VERSION "3.4.0"

NS_ :

BS_:

BU_: User ADM_PC_BI25

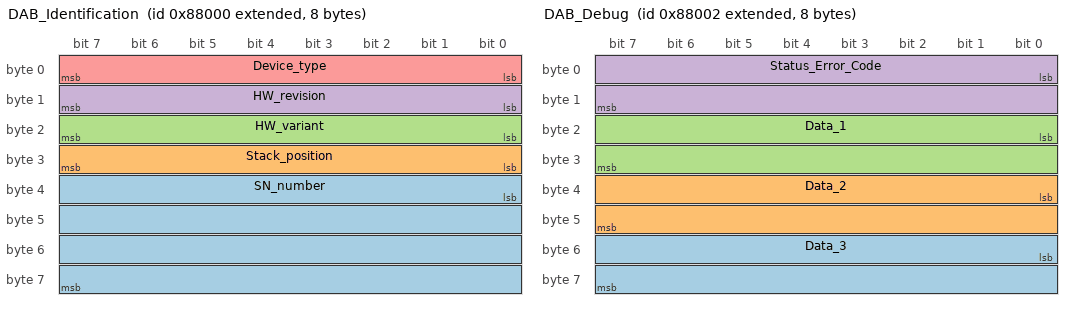
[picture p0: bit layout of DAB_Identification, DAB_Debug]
BO_ 2148040704 DAB_Identification: 8 ADM_PC_BI25
 SG_ SN_number : 32|32@1+ (1,0) [0|0] ""  User
 SG_ Stack_position : 24|8@1+ (1,0) [0|0] ""  User
 SG_ HW_variant : 16|8@1+ (1,0) [0|0] ""  User
 SG_ HW_revision : 8|8@1+ (1,0) [0|0] ""  User
 SG_ Device_type : 0|8@1+ (1,0) [0|0] ""  User

BO_ 2148040705 DAB_FwInfo: 8 ADM_PC_BI25
 SG_ FW_info_mux M : 56|8@1+ (1,0) [0|0] "" Vector__XXX
 SG_ FW_datecode_13 m3 : 48|8@1+ (1,0) [0|0] ""  User
 SG_ FW_datecode_6 m2 : 48|8@1+ (1,0) [0|0] ""  User
 SG_ FW_revision_13 m1 : 48|8@1+ (1,0) [0|0] ""  User
 SG_ FW_revision_6 m0 : 48|8@1+ (1,0) [0|0] ""  User
 SG_ FW_datecode_12 m3 : 40|8@1+ (1,0) [0|0] ""  User
 SG_ FW_datecode_5 m2 : 40|8@1+ (1,0) [0|0] ""  User
 SG_ FW_revision_12 m1 : 40|8@1+ (1,0) [0|0] ""  User
 SG_ FW_revision_5 m0 : 40|8@1+ (1,0) [0|0] ""  User
 SG_ FW_datecode_11 m3 : 32|8@1+ (1,0) [0|0] ""  User
 SG_ FW_datecode_4 m2 : 32|8@1+ (1,0) [0|0] ""  User
 SG_ FW_revision_11 m1 : 32|8@1+ (1,0) [0|0] ""  User
 SG_ FW_revision_4 m0 : 32|8@1+ (1,0) [0|0] ""  User
 SG_ FW_datecode_10 m3 : 24|8@1+ (1,0) [0|0] ""  User
 SG_ FW_datecode_3 m2 : 24|8@1+ (1,0) [0|0] ""  User
 SG_ FW_revision_10 m1 : 24|8@1+ (1,0) [0|0] ""  User
 SG_ FW_revision_3 m0 : 24|8@1+ (1,0) [0|0] ""  User
 SG_ FW_datecode_9 m3 : 16|8@1+ (1,0) [0|0] ""  User
 SG_ FW_datecode_2 m2 : 16|8@1+ (1,0) [0|0] ""  User
 SG_ FW_revision_9 m1 : 16|8@1+ (1,0) [0|0] ""  User
 SG_ FW_revision_2 m0 : 16|8@1+ (1,0) [0|0] ""  User
 SG_ FW_datecode_8 m3 : 8|8@1+ (1,0) [0|0] ""  User
 SG_ FW_datecode_1 m2 : 8|8@1+ (1,0) [0|0] ""  User
 SG_ FW_revision_8 m1 : 8|8@1+ (1,0) [0|0] ""  User
 SG_ FW_revision_1 m0 : 8|8@1+ (1,0) [0|0] ""  User
 SG_ FW_datecode_7 m3 : 0|8@1+ (1,0) [0|0] ""  User
 SG_ FW_datecode_0 m2 : 0|8@1+ (1,0) [0|0] ""  User
 SG_ FW_revision_7 m1 : 0|8@1+ (1,0) [0|0] ""  User
 SG_ FW_revision_0 m0 : 0|8@1+ (1,0) [0|0] ""  User

BO_ 2148040706 DAB_Debug: 8 ADM_PC_BI25
 SG_ Data_3 : 48|16@1+ (1,0) [0|0] ""  User
 SG_ Data_2 : 32|16@1+ (1,0) [0|0] ""  User
 SG_ Data_1 : 16|16@1+ (1,0) [0|0] ""  User
 SG_ Status_Error_Code : 0|16@1+ (1,0) [0|0] ""  User

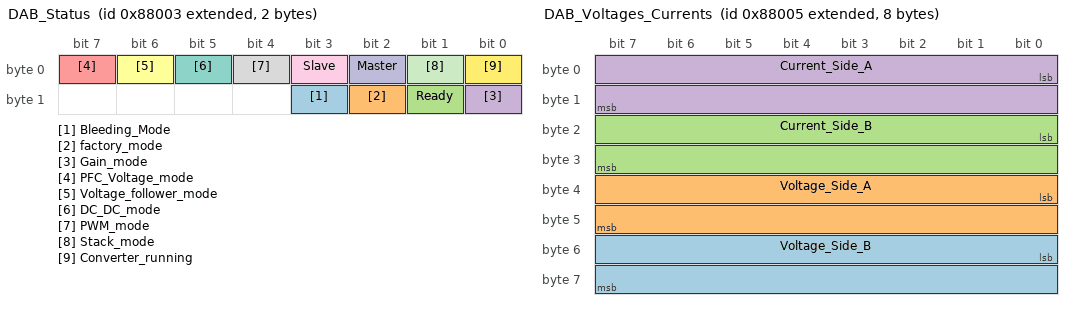
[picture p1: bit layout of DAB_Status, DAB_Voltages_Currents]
BO_ 2148040707 DAB_Status: 2 ADM_PC_BI25
 SG_ Bleeding_Mode : 11|1@1+ (1,0) [0|0] ""  User
 SG_ factory_mode : 10|1@1+ (1,0) [0|0] ""  User
 SG_ Ready : 9|1@1+ (1,0) [0|0] ""  User
 SG_ Gain_mode : 8|1@1+ (1,0) [0|0] ""  User
 SG_ PFC_Voltage_mode : 7|1@1+ (1,0) [0|0] ""  User
 SG_ Voltage_follower_mode : 6|1@1+ (1,0) [0|0] ""  User
 SG_ DC_DC_mode : 5|1@1+ (1,0) [0|0] ""  User
 SG_ PWM_mode : 4|1@1+ (1,0) [0|0] ""  User
 SG_ Slave : 3|1@1+ (1,0) [0|0] ""  User
 SG_ Master : 2|1@1+ (1,0) [0|0] ""  User
 SG_ Stack_mode : 1|1@1+ (1,0) [0|0] ""  User
 SG_ Converter_running : 0|1@1+ (1,0) [0|0] ""  User

BO_ 2148040708 DAB_Faults: 3 ADM_PC_BI25
 SG_ Low_Input_voltage : 23|1@1+ (1,0) [0|0] ""  User
 SG_ Transformer_2_overtemperature : 22|1@1+ (1,0) [0|0] ""  User
 SG_ Transformer_1_overtemperature : 21|1@1+ (1,0) [0|0] ""  User
 SG_ WCH : 20|1@1+ (1,0) [0|0] ""  User
 SG_ ADC : 19|1@1+ (1,0) [0|0] ""  User
 SG_ NFO : 18|1@1+ (1,0) [0|0] ""  User
 SG_ System : 17|1@1+ (1,0) [0|0] ""  User
 SG_ EEPROM_failure : 16|1@1+ (1,0) [0|0] ""  User
 SG_ Measurement_system_failure : 15|1@1+ (1,0) [0|0] ""  User
 SG_ Control_response_timedout : 14|1@1+ (1,0) [0|0] ""  User
 SG_ CAN_failure : 13|1@1+ (1,0) [0|0] ""  User
 SG_ Switching_failure : 12|1@1+ (1,0) [0|0] ""  User
 SG_ Bar_B_overtemperature : 11|1@1+ (1,0) [0|0] ""  User
 SG_ Bar_A_overtemperature : 10|1@1+ (1,0) [0|0] ""  User
 SG_ Voltage_Side_B_overvoltage : 9|1@1+ (1,0) [0|0] ""  User
 SG_ Voltage_Side_B_undervoltage : 8|1@1+ (1,0) [0|0] ""  User
 SG_ Voltage_Side_A_overvoltage : 7|1@1+ (1,0) [0|0] ""  User
 SG_ Voltage_Side_A_undervoltage : 6|1@1+ (1,0) [0|0] ""  User
 SG_ Current_Phase_Side_B_overcurrent : 5|1@1+ (1,0) [0|0] ""  User
 SG_ Current_Phase_Side_A_overcurrent : 4|1@1+ (1,0) [0|0] ""  User
 SG_ Current_Side_B_overcurrent : 3|1@1+ (1,0) [0|0] ""  User
 SG_ Current_Side_A_overcurrent : 2|1@1+ (1,0) [0|0] ""  User
 SG_ Protection_trip_external : 1|1@1+ (1,0) [0|0] ""  User
 SG_ Protection_trip_internal : 0|1@1+ (1,0) [0|0] ""  User

BO_ 2148040709 DAB_Voltages_Currents: 8 ADM_PC_BI25
 SG_ Voltage_Side_B : 48|16@1- (0.1,0) [0|0] "V"  User
 SG_ Voltage_Side_A : 32|16@1- (0.1,0) [0|0] "V"  User
 SG_ Current_Side_B : 16|16@1- (0.01,0) [0|0] "A"  User
 SG_ Current_Side_A : 0|16@1- (0.01,0) [0|0] "A"  User

BO_ 2148040710 DAB_Phase_Currents: 4 ADM_PC_BI25
 SG_ Current_Phase_Side_B : 16|16@1- (0.01,0) [0|0] "A"  User
 SG_ Current_Phase_Side_A : 0|16@1- (0.01,0) [0|0] "A"  User

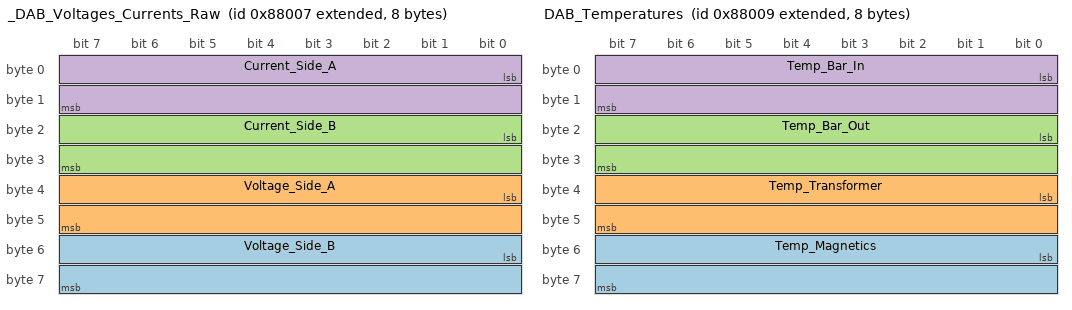
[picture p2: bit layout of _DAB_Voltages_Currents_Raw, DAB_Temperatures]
BO_ 2148040711 _DAB_Voltages_Currents_Raw: 8 ADM_PC_BI25
 SG_ Voltage_Side_B : 48|16@1- (1,0) [0|0] ""  User
 SG_ Voltage_Side_A : 32|16@1+ (1,0) [0|0] ""  User
 SG_ Current_Side_B : 16|16@1- (1,0) [0|0] ""  User
 SG_ Current_Side_A : 0|16@1+ (1,0) [0|0] ""  User

BO_ 2148040712 _DAB_Phase_Currents_Raw: 8 ADM_PC_BI25
 SG_ Current_Phase_Side_B : 16|16@1+ (1,0) [0|0] ""  User
 SG_ Current_Phase_Side_A : 0|16@1+ (1,0) [0|0] ""  User

BO_ 2148040713 DAB_Temperatures: 8 ADM_PC_BI25
 SG_ Temp_Magnetics : 48|16@1- (0.01,0) [0|0] "°C"  User
 SG_ Temp_Transformer : 32|16@1- (0.01,0) [0|0] "°C"  User
 SG_ Temp_Bar_Out : 16|16@1- (0.01,0) [0|0] "°C"  User
 SG_ Temp_Bar_In : 0|16@1- (0.01,0) [0|0] "°C"  User

BO_ 2148040714 DAB_Setpoints_PWM_Phase: 4 ADM_PC_BI25
 SG_ Phase_B : 16|16@1- (0.003,0) [0|0] "°"  User
 SG_ Phase_A : 0|16@1- (0.003,0) [0|0] "°"  User

BO_ 2148040718 _DAB_Broadcast: 8 User
 SG_ Diagnostics_Index M : 56|8@1+ (1,0) [0|0] "" Vector__XXX
 SG_ Port_B m1 : 24|16@1- (0.01,0) [0|0] "A"  ADM_PC_BI25
 SG_ Port_A m1 : 8|16@1- (0.01,0) [0|0] "A"  ADM_PC_BI25
 SG_ Group_ID : 5|3@1+ (1,0) [0|0] ""  ADM_PC_BI25
 SG_ Stack_position : 0|5@1+ (1,0) [0|0] ""  ADM_PC_BI25

BO_ 2148040719 DAB_Group_Info: 1 ADM_PC_BI25
 SG_ Group_ID : 0|8@1+ (1,0) [0|0] ""  User

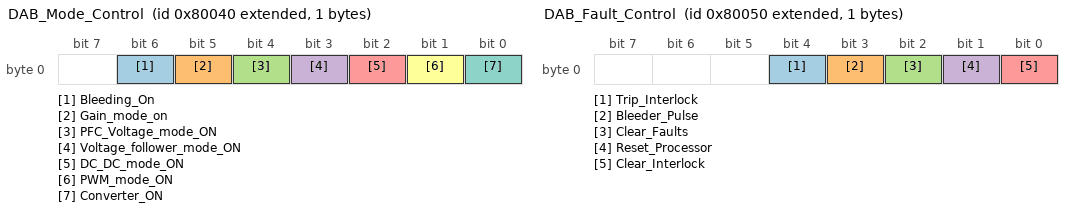
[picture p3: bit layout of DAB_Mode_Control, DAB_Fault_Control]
BO_ 2148008000 DAB_Mode_Control: 1 User
 SG_ Bleeding_On : 6|1@1+ (1,0) [0|0] ""  ADM_PC_BI25
 SG_ Gain_mode_on : 5|1@1+ (1,0) [0|0] ""  ADM_PC_BI25
 SG_ PFC_Voltage_mode_ON : 4|1@1+ (1,0) [0|0] ""  ADM_PC_BI25
 SG_ Voltage_follower_mode_ON : 3|1@1+ (1,0) [0|0] ""  ADM_PC_BI25
 SG_ DC_DC_mode_ON : 2|1@1+ (1,0) [0|0] ""  ADM_PC_BI25
 SG_ PWM_mode_ON : 1|1@1+ (1,0) [0|0] ""  ADM_PC_BI25
 SG_ Converter_ON : 0|1@1+ (1,0) [0|0] ""  ADM_PC_BI25

BO_ 2148008012 DAB_Group_Control: 1 User
 SG_ Group_ID : 0|8@1+ (1,0) [0|0] ""  ADM_PC_BI25

BO_ 2148008016 DAB_Fault_Control: 1 User
 SG_ Trip_Interlock : 4|1@1+ (1,0) [0|0] ""  ADM_PC_BI25
 SG_ Bleeder_Pulse : 3|1@1+ (1,0) [0|0] ""  ADM_PC_BI25
 SG_ Clear_Faults : 2|1@1+ (1,0) [0|0] ""  ADM_PC_BI25
 SG_ Reset_Processor : 1|1@1+ (1,0) [0|0] ""  ADM_PC_BI25
 SG_ Clear_Interlock : 0|1@1+ (1,0) [0|0] ""  ADM_PC_BI25

BO_ 2148008006 DAB_Current_Setpoint_Control: 4 User
 SG_ Negative_Current_setpoint : 16|16@1- (0.01,0) [-55|55] "A"  ADM_PC_BI25
 SG_ Positive_Current_setpoint : 0|16@1- (0.01,0) [-55|55] "A"  ADM_PC_BI25

BO_ 2148008007 DAB_Voltage_Setpoint_Control: 2 User
 SG_ Voltage_setpoint : 0|16@1+ (0.1,0) [0|1000] "V"  ADM_PC_BI25

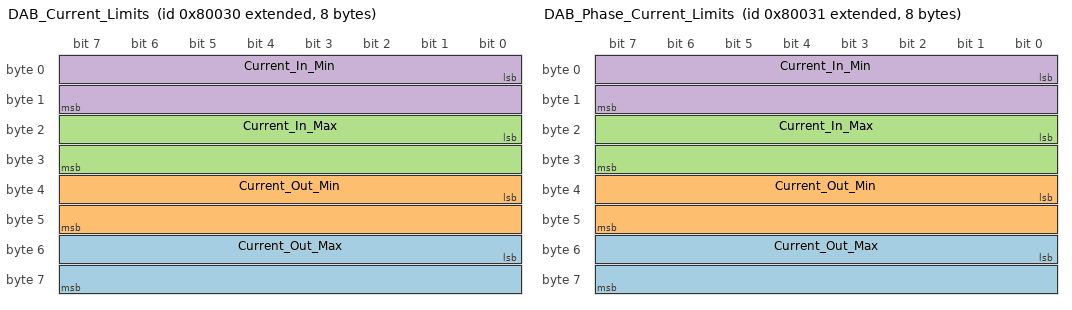
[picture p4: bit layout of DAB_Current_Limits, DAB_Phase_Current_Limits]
BO_ 2148007984 DAB_Current_Limits: 8 User
 SG_ Current_Out_Max : 48|16@1- (0.01,0) [-60|60] "A"  ADM_PC_BI25
 SG_ Current_Out_Min : 32|16@1- (0.01,0) [-60|60] "A"  ADM_PC_BI25
 SG_ Current_In_Max : 16|16@1- (0.01,0) [-60|60] "A"  ADM_PC_BI25
 SG_ Current_In_Min : 0|16@1- (0.01,0) [-60|60] "A"  ADM_PC_BI25

BO_ 2148007985 DAB_Phase_Current_Limits: 8 User
 SG_ Current_Out_Max : 48|16@1- (0.01,0) [-60|60] "A"  ADM_PC_BI25
 SG_ Current_Out_Min : 32|16@1- (0.01,0) [-60|60] "A"  ADM_PC_BI25
 SG_ Current_In_Max : 16|16@1- (0.01,0) [-60|60] "A"  ADM_PC_BI25
 SG_ Current_In_Min : 0|16@1- (0.01,0) [-60|60] "A"  ADM_PC_BI25

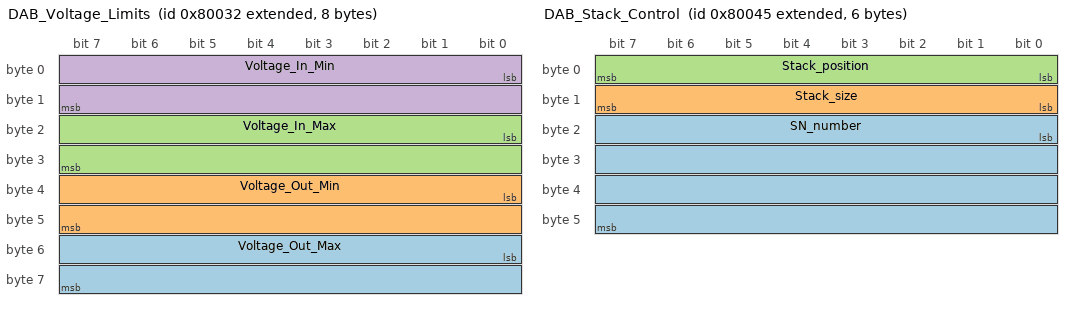
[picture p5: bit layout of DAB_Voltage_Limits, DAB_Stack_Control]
BO_ 2148007986 DAB_Voltage_Limits: 8 User
 SG_ Voltage_Out_Max : 48|16@1- (0.1,0) [0|850] "V"  ADM_PC_BI25
 SG_ Voltage_Out_Min : 32|16@1- (0.1,0) [0|850] "V"  ADM_PC_BI25
 SG_ Voltage_In_Max : 16|16@1- (0.1,0) [0|850] "V"  ADM_PC_BI25
 SG_ Voltage_In_Min : 0|16@1- (0.1,0) [0|850] "V"  ADM_PC_BI25

BO_ 2148040769 _DAB_Calibration_Adc_Fs: 6 ADM_PC_BI25
 SG_ Adc_Index M : 32|16@1+ (1,0) [0|0] "" Vector__XXX
 SG_ Current_Phase_Side_B m5 : 0|32@1+ (1,0) [0|0] "Fullscale"  User
 SG_ Voltage_Side_B m4 : 0|32@1+ (1,0) [0|0] "Fullscale"  User
 SG_ Voltage_Side_A m3 : 0|32@1+ (1,0) [0|0] "Fullscale"  User
 SG_ Current_Phase_Side_A m2 : 0|32@1+ (1,0) [0|0] "Fullscale"  User
 SG_ Current_Side_B m1 : 0|32@1+ (1,0) [0|0] "Fullscale"  User
 SG_ Current_Side_A m0 : 0|32@1+ (1,0) [0|0] "Fullscale"  User

BO_ 2148008001 _DAB_Calibration_Offset_Update: 6 User
 SG_ CRC : 32|16@1+ (1,0) [0|0] "-"  ADM_PC_BI25
 SG_ Calibration_Index M : 16|16@1+ (1,0) [0|0] "" Vector__XXX
 SG_ Current_Phase_Side_B m5 : 0|16@1- (1,0) [0|0] "ADC Counts"  ADM_PC_BI25
 SG_ Voltage_Side_B m4 : 0|16@1- (1,0) [0|0] "ADC Counts"  ADM_PC_BI25
 SG_ Voltage_Side_A m3 : 0|16@1- (1,0) [0|0] "ADC Counts"  ADM_PC_BI25
 SG_ Current_Phase_Side_A m2 : 0|16@1- (1,0) [0|0] "ADC Counts"  ADM_PC_BI25
 SG_ Current_Side_B m1 : 0|16@1- (1,0) [0|0] "ADC Counts"  ADM_PC_BI25
 SG_ Current_Side_A m0 : 0|16@1- (1,0) [0|0] "ADC Counts"  ADM_PC_BI25

BO_ 2148008002 _DAB_Calibration_Scale_Update: 6 User
 SG_ CRC : 32|16@1+ (1,0) [0|0] "-"  ADM_PC_BI25
 SG_ Calibration_Index M : 16|16@1+ (1,0) [0|0] "" Vector__XXX
 SG_ Current_Phase_Side_B m5 : 0|16@1- (1,0) [0|0] "ADC Counts"  ADM_PC_BI25
 SG_ Voltage_Side_B m4 : 0|16@1- (1,0) [0|0] "ADC Counts"  ADM_PC_BI25
 SG_ Voltage_Side_A m3 : 0|16@1- (1,0) [0|0] "ADC Counts"  ADM_PC_BI25
 SG_ Current_Phase_Side_A m2 : 0|16@1- (1,0) [0|0] "ADC Counts"  ADM_PC_BI25
 SG_ Current_Side_B m1 : 0|16@1- (1,0) [0|0] "ADC Counts"  ADM_PC_BI25
 SG_ Current_Side_A m0 : 0|16@1- (1,0) [0|0] "ADC Counts"  ADM_PC_BI25

BO_ 2148040770 _DAB_Calibration_Adc_Scale: 6 ADM_PC_BI25
 SG_ Adc_Index M : 32|16@1+ (1,0) [0|0] "" Vector__XXX
 SG_ Current_Phase_Side_B m5 : 0|32@1+ (1,0) [0|0] "1 / adc_bins"  User
 SG_ Voltage_Side_B m4 : 0|32@1- (1,0) [0|0] "1 / adc_bins"  User
 SG_ Voltage_Side_A m3 : 0|32@1- (1,0) [0|0] "1 / adc_bins"  User
 SG_ Current_Phase_Side_A m2 : 0|32@1- (1,0) [0|0] "1 / adc_bins"  User
 SG_ Current_Side_B m1 : 0|32@1- (1,0) [0|0] "1 / adc_bins"  User
 SG_ Current_Side_A m0 : 0|32@1- (1,0) [0|0] "1 / adc_bins"  User

BO_ 2148008003 DAB_PWM_Phase_Control: 4 User
 SG_ Phase_B : 16|16@1- (0.003,0) [0|0] "°"  ADM_PC_BI25
 SG_ Phase_A : 0|16@1- (0.003,0) [0|0] "°"  ADM_PC_BI25

BO_ 2148008004 CLLC_PWM_Frequency_Control: 2 User
 SG_ PWM_frequency : 0|16@1+ (10,0) [0|0] "Hz"  ADM_PC_BI25

BO_ 2148040776 CLLC_PWM_Frequency_value: 4 ADM_PC_BI25
 SG_ frequency : 0|16@1+ (10,0) [0|0] "Hz"  User

BO_ 2148008005 DAB_Stack_Control: 6 User
 SG_ SN_number : 16|32@1+ (1,0) [0|0] ""  ADM_PC_BI25
 SG_ Stack_size : 8|8@1+ (1,0) [0|0] ""  ADM_PC_BI25
 SG_ Stack_position : 0|8@1+ (1,0) [0|0] ""  ADM_PC_BI25

BO_ 2148008008 CLLC_PWM_Gain_Control: 2 User
 SG_ Gain : 0|16@1+ (0.01,0) [0|0] "none"  ADM_PC_BI25

BO_ 2148040849 Data_phase_shift: 4 ADM_PC_BI25
 SG_ phase_shift_b : 16|16@1+ (0.1,0) [0|0] "Hz"  User
 SG_ phase_shift_a : 0|16@1- (0.1,0) [0|0] "V"  User

BO_ 2148008009 CLLC_PWM_Phase_Mode: 1 User
 SG_ phase_mode : 0|8@1+ (1,0) [0|0] ""  ADM_PC_BI25

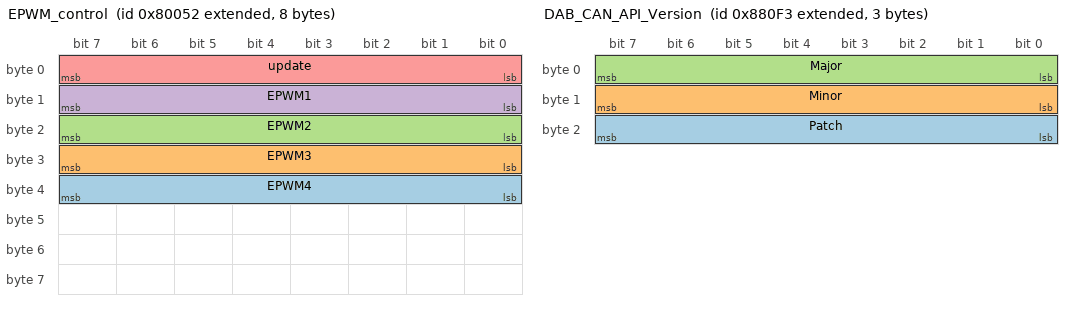
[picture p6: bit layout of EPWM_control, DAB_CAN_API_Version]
BO_ 2148008018 EPWM_control: 8 User
 SG_ EPWM4 : 32|8@1+ (1,0) [0|0] ""  ADM_PC_BI25
 SG_ EPWM3 : 24|8@1+ (1,0) [0|0] ""  ADM_PC_BI25
 SG_ EPWM2 : 16|8@1+ (1,0) [0|0] ""  ADM_PC_BI25
 SG_ EPWM1 : 8|8@1+ (1,0) [0|0] ""  ADM_PC_BI25
 SG_ update : 0|8@1+ (1,0) [0|0] ""  ADM_PC_BI25

BO_ 2148040947 DAB_CAN_API_Version: 3 ADM_PC_BI25
 SG_ Patch : 16|8@1+ (1,0) [0|0] ""  User
 SG_ Minor : 8|8@1+ (1,0) [0|0] ""  User
 SG_ Major : 0|8@1+ (1,0) [0|0] ""  User

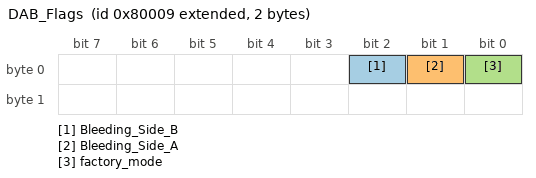
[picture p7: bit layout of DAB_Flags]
BO_ 2148007945 DAB_Flags: 2 User
 SG_ Bleeding_Side_B : 2|1@1+ (1,0) [0|0] ""  ADM_PC_BI25
 SG_ Bleeding_Side_A : 1|1@1+ (1,0) [0|0] ""  ADM_PC_BI25
 SG_ factory_mode : 0|1@1+ (1,0) [0|0] ""  ADM_PC_BI25

BO_ 2148040959 CLLC_Fault_Label: 4 ADM_PC_BI25
 SG_ Faults : 0|16@1+ (1,0) [0|0] ""  User

BO_ 2148008106 ADB_Schedule_Flag: 2 User
 SG_ ADB_Preset_1 : 0|1@1+ (1,0) [0|0] ""  ADM_PC_BI25

CM_ BO_ 2148040704 "Identification of the device";
CM_ SG_ 2148040704 SN_number "Unique module serial number";
CM_ SG_ 2148040704 Stack_position "Position of the module within the stack";
CM_ SG_ 2148040704 HW_variant "The DSP firmware revision number";
CM_ SG_ 2148040704 HW_revision "The hardware revision number";
CM_ SG_ 2148040704 Device_type " The device identification field, uniquely identifies the sender in the network. ";
CM_ BO_ 2148040705 "Git revision of the DSP firmware";
CM_ SG_ 2148040705 FW_datecode_13 "Character 13";
CM_ SG_ 2148040705 FW_datecode_6 "Character 3";
CM_ SG_ 2148040705 FW_revision_13 "Character 13";
CM_ SG_ 2148040705 FW_revision_6 "Character 3";
CM_ SG_ 2148040705 FW_datecode_12 "Character 12";
CM_ SG_ 2148040705 FW_datecode_5 "Character 3";
CM_ SG_ 2148040705 FW_revision_12 "Character 12";
CM_ SG_ 2148040705 FW_revision_5 "Character 3";
CM_ SG_ 2148040705 FW_datecode_11 "Character 11";
CM_ SG_ 2148040705 FW_datecode_4 "Character 3";
CM_ SG_ 2148040705 FW_revision_11 "Character 11";
CM_ SG_ 2148040705 FW_revision_4 "Character 3";
CM_ SG_ 2148040705 FW_datecode_10 "Character 10";
CM_ SG_ 2148040705 FW_datecode_3 "Character 3";
CM_ SG_ 2148040705 FW_revision_10 "Character 10";
CM_ SG_ 2148040705 FW_revision_3 "Character 3";
CM_ SG_ 2148040705 FW_datecode_9 "Character 9";
CM_ SG_ 2148040705 FW_datecode_2 "Character 2";
CM_ SG_ 2148040705 FW_revision_9 "Character 9";
CM_ SG_ 2148040705 FW_revision_2 "Character 2";
CM_ SG_ 2148040705 FW_datecode_8 "Character 8";
CM_ SG_ 2148040705 FW_datecode_1 "Character 1";
CM_ SG_ 2148040705 FW_revision_8 "Character 8";
CM_ SG_ 2148040705 FW_revision_1 "Character 1";
CM_ SG_ 2148040705 FW_datecode_7 "Character 7";
CM_ SG_ 2148040705 FW_datecode_0 "Character 0";
CM_ SG_ 2148040705 FW_revision_7 "Character 7";
CM_ SG_ 2148040705 FW_revision_0 "Character 0";
CM_ BO_ 2148040706 "Values for debugging of HW/SW problems";
CM_ SG_ 2148040706 Data_3 "Additional information for the error/status";
CM_ SG_ 2148040706 Data_2 "Additional information for the error/status";
CM_ SG_ 2148040706 Data_1 "Additional information for the error/status";
CM_ SG_ 2148040706 Status_Error_Code "Main status / error code as defined in errno/errno.h";
CM_ BO_ 2148040707 "Status bitfield";
CM_ SG_ 2148040707 Bleeding_Mode "Indicates if converter is in Bleeding mode.";
CM_ SG_ 2148040707 factory_mode "Indicates if converter is in factory mode.";
CM_ SG_ 2148040707 Ready "Indicates if converter is ready for operation.";
CM_ SG_ 2148040707 Gain_mode " Indicates if the converter is in Gain Mode.";
CM_ SG_ 2148040707 PFC_Voltage_mode " Indicates if the converter is in PFC Voltage mode. ";
CM_ SG_ 2148040707 Voltage_follower_mode " Indicates if the converter is in Voltage follower mode. ";
CM_ SG_ 2148040707 DC_DC_mode " Indicates if the converter is in DC DC mode with automatic bi-dir angle control. ";
CM_ SG_ 2148040707 PWM_mode " Indicates if the converter is in PWM mode, and therefore working in open loop. ";
CM_ SG_ 2148040707 Slave "Indicates if the current converter is a Slave in the stack.";
CM_ SG_ 2148040707 Master "Indicates if the current converter is the Master in the stack.";
CM_ SG_ 2148040707 Stack_mode "Indicates if running in stack mode.";
CM_ SG_ 2148040707 Converter_running "Indicates that the converter is running, and its output is active.";
CM_ BO_ 2148040708 "Fault bitfield";
CM_ SG_ 2148040708 Low_Input_voltage "
            This flag is asserted when the Input voltage is low than 500V.
        ";
CM_ SG_ 2148040708 Transformer_2_overtemperature "
            This flag is asserted when the temperature of the Bar B block is too high.
        ";
CM_ SG_ 2148040708 Transformer_1_overtemperature "
            This flag is asserted when the temperature of the Bar B block is too high.
        ";
CM_ SG_ 2148040708 EEPROM_failure "
            The configuration EEPROM failed to load or save the module configuration.
        ";
CM_ SG_ 2148040708 Measurement_system_failure "
            The voltages/currents measurement system is malfunctionning, and readouts are not
            guaranteed to be accurate.
        ";
CM_ SG_ 2148040708 Control_response_timedout "
            The control system did not answer within the allowed time window, and a time out
            condition was triggered. The converter is switched off as the control system is
            not present.
        ";
CM_ SG_ 2148040708 CAN_failure "
            CAN bus or transceiver not operating properly.
        ";
CM_ SG_ 2148040708 Switching_failure "
            Failure in the MOSFET block or in their drivers.
        ";
CM_ SG_ 2148040708 Bar_B_overtemperature "
            This flag is asserted when the temperature of the Bar B block is too high.
        ";
CM_ SG_ 2148040708 Bar_A_overtemperature "
            This flag is asserted when the temperature of the Bar A block is too high.
        ";
CM_ SG_ 2148040708 Voltage_Side_B_overvoltage "
            Indicates an overvoltage event Voltage Out. The overvoltage event is triggered when
            the measured phase voltage is over the programmed / absolute voltage limit.
        ";
CM_ SG_ 2148040708 Voltage_Side_B_undervoltage "
            Indicates an undervoltage event on Voltage Out. The undervoltage event is triggered
            when the measured voltage is under the programmed / absolute voltage limit.
        ";
CM_ SG_ 2148040708 Voltage_Side_A_overvoltage "
            Indicates an overvoltage event Voltage In. The overvoltage event is triggered when
            the measured phase voltage is over the programmed / absolute voltage limit.
        ";
CM_ SG_ 2148040708 Voltage_Side_A_undervoltage "
            Indicates an undervoltage event on Voltage In. The undervoltage event is triggered
            when the measured voltage is under the programmed / absolute voltage limit.
        ";
CM_ SG_ 2148040708 Current_Phase_Side_B_overcurrent "
            Indicates an overcurrent event on output phase current. The overcurrent event is
            triggered when the measured current is over the programmed / absolute current limit.
        ";
CM_ SG_ 2148040708 Current_Phase_Side_A_overcurrent "
            Indicates an overcurrent event on input phase current. The overcurrent event is
            triggered when the measured current is over the programmed / absolute current limit.
        ";
CM_ SG_ 2148040708 Current_Side_B_overcurrent "
            Indicates an overcurrent event on output current. The overcurrent event is
            triggered when the measured current is over the programmed / absolute current limit.
        ";
CM_ SG_ 2148040708 Current_Side_A_overcurrent "
            Indicates an overcurrent event on input current. The overcurrent event is triggered
            when the measured phase current is over the programmed / absolute current limit.
        ";
CM_ SG_ 2148040708 Protection_trip_external " This flag is asserted if the interlock is open due to an external condition received in the module. ";
CM_ SG_ 2148040708 Protection_trip_internal " This flag is asserted if the interlock is open due to an internal fault condition (self-protection). ";
CM_ BO_ 2148040709 "Voltages and currents of Input/Output";
CM_ SG_ 2148040709 Voltage_Side_B "Output voltage of the converter.";
CM_ SG_ 2148040709 Voltage_Side_A "Input voltage of the converter.";
CM_ SG_ 2148040709 Current_Side_B " Input current of the converter (direction from input to output is positive). ";
CM_ SG_ 2148040709 Current_Side_A " Input current of the converter (direction from input to output is positive). ";
CM_ BO_ 2148040710 "Phase currents of Input/Output";
CM_ SG_ 2148040710 Current_Phase_Side_B " Input phase current of the converter (direction from input to output is positive). ";
CM_ SG_ 2148040710 Current_Phase_Side_A " Input phase current of the converter (direction from input to output is positive). ";
CM_ BO_ 2148040711 "Raw Voltages and currents of Input/Output";
CM_ BO_ 2148040712 "Raw ADC values from the Phase current sensors";
CM_ BO_ 2148040713 "Readouts of the module temperature sensors";
CM_ SG_ 2148040713 Temp_Magnetics "Temperature of the Magnetic B block";
CM_ SG_ 2148040713 Temp_Transformer "Temperature of the Bar B block";
CM_ SG_ 2148040713 Temp_Bar_Out "Temperature of the Bar A block";
CM_ SG_ 2148040713 Temp_Bar_In "Temperature of the Bar A block";
CM_ BO_ 2148040714 "PWM duty cycle control";
CM_ SG_ 2148040714 Phase_B "PWM Phase setpoint.";
CM_ SG_ 2148040714 Phase_A "PWM Phase setpoint.";
CM_ BO_ 2148040718 "All DABs will listen to this message";
CM_ SG_ 2148040718 Port_B "'Output' port B current.";
CM_ SG_ 2148040718 Port_A "'Input' port A current. ";
CM_ SG_ 2148040718 Group_ID "Sender Group ID";
CM_ SG_ 2148040718 Stack_position "Sender Stack position";
CM_ BO_ 2148040719 "Contains the Group ID of the device";
CM_ SG_ 2148040719 Group_ID "Group ID of the device";
CM_ BO_ 2148008000 "Operation Mode control: sets the converter operation mode";
CM_ SG_ 2148008000 Bleeding_On "Enable the Bleeding mode (this will set the converter in open loop).";
CM_ SG_ 2148008000 Gain_mode_on "Enable the GAIN mode (this will set the converter in open loop).";
CM_ SG_ 2148008000 PFC_Voltage_mode_ON "This mode regulates output (port B) current/voltage while sending voltage commands to an Upstream AFE working as PFC (AC to DC), to ensure a 1:1 voltage ratio.";
CM_ SG_ 2148008000 Voltage_follower_mode_ON "This mode will regulate a 1:1 ratio voltage from A to B (A is reference voltage)";
CM_ SG_ 2148008000 DC_DC_mode_ON "Enable the DC DC mode (this will set the converter in automatic angle control). ";
CM_ SG_ 2148008000 PWM_mode_ON "Enable the PWM mode (this will set the converter in open loop).";
CM_ SG_ 2148008000 Converter_ON "Enable the converter";
CM_ BO_ 2148008012 "Set the Group ID of the device";
CM_ SG_ 2148008012 Group_ID "Desired group ID for the device";
CM_ BO_ 2148008016 "Fault Control: actions to clear faults and reset the system";
CM_ SG_ 2148008016 Trip_Interlock "Trips the converter interlock";
CM_ SG_ 2148008016 Bleeder_Pulse "Bleed out output";
CM_ SG_ 2148008016 Clear_Faults "Clear software faults";
CM_ SG_ 2148008016 Reset_Processor "Reset the converter DSP";
CM_ SG_ 2148008016 Clear_Interlock "Clears the converter interlock";
CM_ BO_ 2148008006 "Current setpoint control";
CM_ SG_ 2148008006 Negative_Current_setpoint "Sets the port B negative current setpoint.";
CM_ SG_ 2148008006 Positive_Current_setpoint "Sets the port B positive current setpoint.";
CM_ BO_ 2148008007 "Voltage setpoint control";
CM_ SG_ 2148008007 Voltage_setpoint "Sets the output voltage setpoint";
CM_ SG_ 2148007984 Current_Out_Max "Maximum allowable output current of the converter.";
CM_ SG_ 2148007984 Current_Out_Min "Minimum allowable output current of the converter.";
CM_ SG_ 2148007984 Current_In_Max "Maximum allowable input current of the converter.";
CM_ SG_ 2148007984 Current_In_Min "Minimum allowable input current of the converter.";
CM_ SG_ 2148007985 Current_Out_Max "Maximum allowable output current of the converter.";
CM_ SG_ 2148007985 Current_Out_Min "Minimum allowable output current of the converter.";
CM_ SG_ 2148007985 Current_In_Max "Maximum allowable input current of the converter.";
CM_ SG_ 2148007985 Current_In_Min "Minimum allowable input current of the converter.";
CM_ BO_ 2148007986 "Set the voltage limits (mminimum and maximum)";
CM_ SG_ 2148007986 Voltage_Out_Max "Minimum allowable output voltage of the converter.";
CM_ SG_ 2148007986 Voltage_Out_Min "Minimum allowable output voltage of the converter.";
CM_ SG_ 2148007986 Voltage_In_Max "Minimum allowable input voltage of the converter.";
CM_ SG_ 2148007986 Voltage_In_Min "Minimum allowable input voltage of the converter.";
CM_ BO_ 2148040769 " Fullscale value of readouts. ";
CM_ BO_ 2148008001 "Update of the calibration table for offsets.";
CM_ SG_ 2148008001 CRC " Checksum of bytes 0 to 2, CRC-CCITT, corresponding to qChecksum (www.qt.io) ";
CM_ BO_ 2148008002 "Update of the calibration table for scales.";
CM_ SG_ 2148008002 CRC " Checksum of bytes 0 to 2, CRC-CCITT, corresponding to qChecksum (www.qt.io) ";
CM_ BO_ 2148040770 " Adc scale (resolution) value of readouts. ";
CM_ BO_ 2148008003 "PWM duty cycle control";
CM_ SG_ 2148008003 Phase_B "PWM Phase setpoint";
CM_ SG_ 2148008003 Phase_A "PWM Phase setpoint";
CM_ BO_ 2148008004 "PWM frequency control";
CM_ SG_ 2148008004 PWM_frequency "Sets the PWM frequency. Active only when the converter is in PWM mode";
CM_ BO_ 2148040776 "PWM duty cycle Readout";
CM_ SG_ 2148040776 frequency "PWM frequency setpoint.";
CM_ BO_ 2148008005 "PFC stack control";
CM_ SG_ 2148008005 SN_number "Unique module serial number";
CM_ SG_ 2148008005 Stack_size "How many PFC converters are in stack in total";
CM_ SG_ 2148008005 Stack_position "The converter position within the stack";
CM_ BO_ 2148008008 "PWM gain control";
CM_ SG_ 2148008008 Gain "Sets voltage gain in open loop";
CM_ BO_ 2148040849 "Readouts of the module phase shifts";
CM_ SG_ 2148040849 phase_shift_b "Phase_shift_B of the Bar A block";
CM_ SG_ 2148040849 phase_shift_a "Phase_shift_A of the Bar A block";
CM_ BO_ 2148008009 "PWM duty cycle control";
CM_ SG_ 2148008009 phase_mode "PWM Phase shift mode/gain mode";
CM_ BO_ 2148008018 "Control the EPWM_control";
CM_ SG_ 2148008018 EPWM4 "Customers MUST NOT USE this bit. If set to 1, EPWM is turned on. ";
CM_ SG_ 2148008018 EPWM3 "Customers MUST NOT USE this bit. If set to 1, EPWM is turned on. ";
CM_ SG_ 2148008018 EPWM2 "Customers MUST NOT USE this bit. If set to 1, EPWM is turned on. ";
CM_ SG_ 2148008018 EPWM1 "Customers MUST NOT USE this bit. If set to 1, EPWM is turned on. ";
CM_ SG_ 2148008018 update "Customers MUST NOT USE this bit. If set to 1, EPWM is turned on. ";
CM_ BO_ 2148040947 "This message declares the version of the API that is provided by the converter. The version follows newer convention.";
CM_ SG_ 2148040947 Patch "The Patch number. This number increases when changes to descriptions and documentation/comments are made";
CM_ SG_ 2148040947 Minor "The Minor version number. This number increases if there are backwards compatible changes, like new messages or the use of previously reserved space";
CM_ SG_ 2148040947 Major "The Major version number. This number increases if there are backwards incompatible changes";
CM_ BO_ 2148007945 "All Flags of the converter";
CM_ SG_ 2148007945 Bleeding_Side_B "Enable Bleeding_Side_B mode";
CM_ SG_ 2148007945 Bleeding_Side_A "Enable Bleeding_Side_A mode";
CM_ SG_ 2148007945 factory_mode "Enable Factory mode";
CM_ BO_ 2148040959 "This message tells the General Status of the converter.";
CM_ SG_ 2148040959 Faults "Faults state";
CM_ BO_ 2148008106 "Chnage to preset of CAN messages for ADB converter";
CM_ SG_ 2148008106 ADB_Preset_1 "Enable Preset mode";
BA_DEF_ BO_  "GenMsgCycleTime" INT 0 65535;
BA_DEF_DEF_  "GenMsgCycleTime" 0;
BA_ "GenMsgCycleTime" BO_ 2148040704 1000;
BA_ "GenMsgCycleTime" BO_ 2148040705 1000;
BA_ "GenMsgCycleTime" BO_ 2148040706 1000;
BA_ "GenMsgCycleTime" BO_ 2148040707 100;
BA_ "GenMsgCycleTime" BO_ 2148040708 1000;
BA_ "GenMsgCycleTime" BO_ 2148040709 100;
BA_ "GenMsgCycleTime" BO_ 2148040710 100;
BA_ "GenMsgCycleTime" BO_ 2148040711 100;
BA_ "GenMsgCycleTime" BO_ 2148040712 100;
BA_ "GenMsgCycleTime" BO_ 2148040713 1000;
BA_ "GenMsgCycleTime" BO_ 2148040714 1000;
BA_ "GenMsgCycleTime" BO_ 2148040718 50;
BA_ "GenMsgCycleTime" BO_ 2148040719 1000;
BA_ "GenMsgCycleTime" BO_ 2148008000 100;
BA_ "GenMsgCycleTime" BO_ 2148008006 100;
BA_ "GenMsgCycleTime" BO_ 2148008007 100;
BA_ "GenMsgCycleTime" BO_ 2148040769 1000;
BA_ "GenMsgCycleTime" BO_ 2148040770 1000;
BA_ "GenMsgCycleTime" BO_ 2148040776 1000;
BA_ "GenMsgCycleTime" BO_ 2148040849 1000;
BA_ "GenMsgCycleTime" BO_ 2148040947 1000;
BA_ "GenMsgCycleTime" BO_ 2148040959 1000;
VAL_ 2148040704 Device_type 8 "ADM_PC_BI25" ;
VAL_ 2148040708 Low_Input_voltage 1 "fault" ;
VAL_ 2148040708 Transformer_2_overtemperature 1 "fault" ;
VAL_ 2148040708 Transformer_1_overtemperature 1 "fault" ;
VAL_ 2148040708 WCH 1 "fault" ;
VAL_ 2148040708 ADC 1 "fault" ;
VAL_ 2148040708 NFO 1 "fault" ;
VAL_ 2148040708 System 1 "fault" ;
VAL_ 2148040708 EEPROM_failure 1 "fault" ;
VAL_ 2148040708 Measurement_system_failure 1 "fault" ;
VAL_ 2148040708 Control_response_timedout 1 "fault" ;
VAL_ 2148040708 CAN_failure 1 "fault" ;
VAL_ 2148040708 Switching_failure 1 "fault" ;
VAL_ 2148040708 Bar_B_overtemperature 1 "fault" ;
VAL_ 2148040708 Bar_A_overtemperature 1 "fault" ;
VAL_ 2148040708 Voltage_Side_B_overvoltage 1 "fault" ;
VAL_ 2148040708 Voltage_Side_B_undervoltage 1 "fault" ;
VAL_ 2148040708 Voltage_Side_A_overvoltage 1 "fault" ;
VAL_ 2148040708 Voltage_Side_A_undervoltage 1 "fault" ;
VAL_ 2148040708 Current_Phase_Side_B_overcurrent 1 "fault" ;
VAL_ 2148040708 Current_Phase_Side_A_overcurrent 1 "fault" ;
VAL_ 2148040708 Current_Side_B_overcurrent 1 "fault" ;
VAL_ 2148040708 Current_Side_A_overcurrent 1 "fault" ;
VAL_ 2148040708 Protection_trip_external 1 "fault" ;
VAL_ 2148040708 Protection_trip_internal 1 "fault" ;
VAL_ 2148040959 Faults 1 "Current_Side_A_overcurrent" 2 "Current_Side_B_overcurrent" 3 "Current_Phase_Side_A_overcurrent" 4 "Current_Phase_Side_B_overcurrent" 5 "Voltage_Side_A_undervoltage" 6 "Voltage_Side_A_overvoltage" 7 "Voltage_Side_B_undervoltage" 8 "Voltage_Side_B_overvoltage" 9 "Bar_A_overtemperature" 10 "Bar_B_overtemperature" 11 "Transformer_1_overtemperature" 12 "Transformer_2_overtemperature" 13 "Low_Input_voltage" 14 "EEPROM_failure" ;
SIG_VALTYPE_ 2148040769 Current_Side_A : 1;
SIG_VALTYPE_ 2148040769 Current_Side_B : 1;
SIG_VALTYPE_ 2148040769 Current_Phase_Side_A : 1;
SIG_VALTYPE_ 2148040769 Voltage_Side_A : 1;
SIG_VALTYPE_ 2148040769 Voltage_Side_B : 1;
SIG_VALTYPE_ 2148040769 Current_Phase_Side_B : 1;
SIG_VALTYPE_ 2148040770 Current_Phase_Side_B : 1;
